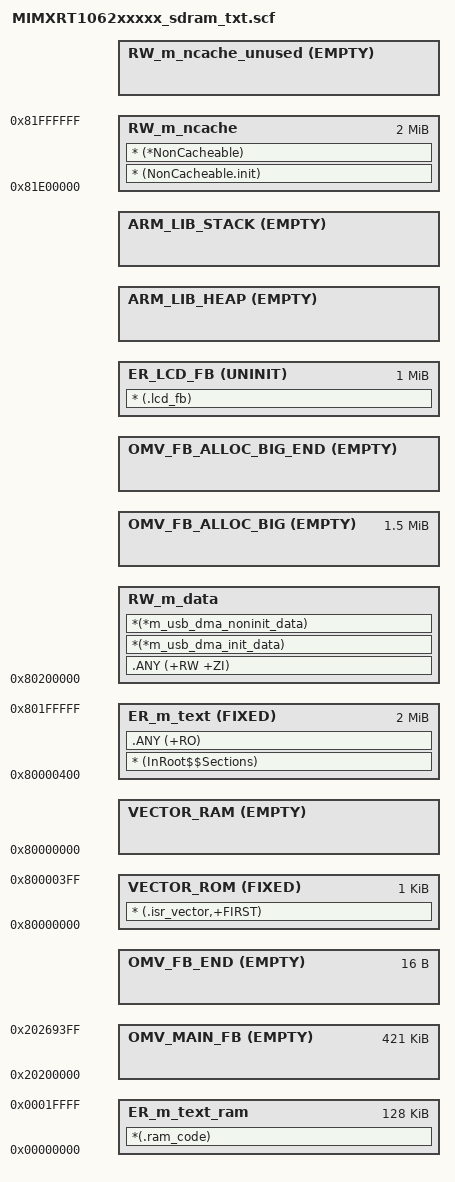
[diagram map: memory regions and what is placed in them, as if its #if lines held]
#!armclang --target=arm-arm-none-eabi -mcpu=cortex-m7 -E -x c
/*
** ###################################################################
**     Processors:          MIMXRT1062CVJ5A
**                          MIMXRT1062CVL5A
**                          MIMXRT1062DVJ6A
**                          MIMXRT1062DVL6A
**
**     Compiler:            Keil ARM C/C++ Compiler
**     Reference manual:    IMXRT1060RM Rev.1, 12/2018 | IMXRT1060SRM Rev.3
**     Version:             rev. 0.1, 2017-01-10
**     Build:               b191015
**
**     Abstract:
**         Linker file for the Keil ARM C/C++ Compiler
**
**     Copyright 2016 Freescale Semiconductor, Inc.
**     Copyright 2016-2019 NXP
**     All rights reserved.
**
**     SPDX-License-Identifier: BSD-3-Clause
**
**     http:                 www.nxp.com
**     mail:                 support@nxp.com
**
** ###################################################################
*/

#define m_interrupts_start             0x80000000
#define m_interrupts_size              0x00000400

#define m_text_start                   0x80000400
#define m_text_size                    0x001FFC00

#define m_text_ram_start               0x00000000
#define m_text_ram_size                0x00020000

#define m_data3_start                   0x20200000
#define m_data3_size                    0x000C0000

#define m_data2_start                  0x20000000
#define m_data2_size                   0x00020000

#define m_data_start                  0x80200000
#define m_data_size                   0x01C00000

#define m_ncache_start                 0x81E00000
#define m_ncache_size                  0x00200000

/* Sizes */
#if (defined(__stack_size__))
  #define Stack_Size                   __stack_size__
#else
  #define Stack_Size                   0x2000
#endif

#if (defined(__heap_size__))
  #define Heap_Size                    __heap_size__
#else
  #define Heap_Size                    0x4000
#endif

#define OMV_MAIN_FB_SIZE	301*1024 //301*1024
#define OMV_FB_ALLOC_SIZE	120*1024 //83*1024
#define OMV_FB_ALLOC_BIG_SIZE  1536*1024

LR_m_text m_interrupts_start m_text_start+m_text_size-m_interrupts_start {   ; load region size_region
  VECTOR_ROM m_interrupts_start FIXED m_interrupts_size { ; load address = execution address
    * (.isr_vector,+FIRST)
  }
  ER_m_text m_text_start FIXED m_text_size { ; load address = execution address
    * (InRoot$$Sections)
    .ANY (+RO)
  }
  VECTOR_RAM m_interrupts_start EMPTY 0 {
  }
  
  ER_m_text_ram m_text_ram_start m_text_ram_size {
	*(.ram_code)
  }
  
  OMV_MAIN_FB 0x20200000 EMPTY OMV_MAIN_FB_SIZE  + OMV_FB_ALLOC_SIZE {}
  OMV_FB_END +0 EMPTY 16 {}	
		
  RW_m_data m_data_start m_data_size-Stack_Size-Heap_Size { ; RW data
    .ANY (+RW +ZI)
    *(*m_usb_dma_init_data)
    *(*m_usb_dma_noninit_data)
  }
  ; <<<
  OMV_FB_ALLOC_BIG +0 EMPTY OMV_FB_ALLOC_BIG_SIZE {}
  OMV_FB_ALLOC_BIG_END +0 EMPTY 0 {}	
  ; <<<
  ER_LCD_FB +0 UNINIT 1024*1024  {
		* (.lcd_fb)
  }
  
  ARM_LIB_HEAP +0 EMPTY Heap_Size {    ; Heap region growing up
  }
  ARM_LIB_STACK m_data_start+m_data_size EMPTY -Stack_Size { ; Stack region growing down
  }
  RW_m_ncache m_ncache_start m_ncache_size { ; ncache RW data
    * (NonCacheable.init)
    * (*NonCacheable)
  }
  RW_m_ncache_unused +0 EMPTY m_ncache_size-ImageLength(RW_m_ncache) { ; Empty region added for MPU configuration
  }
}
